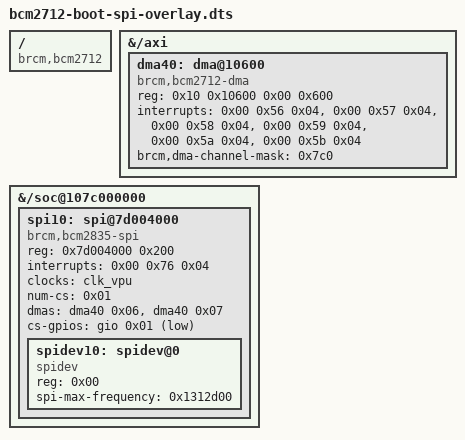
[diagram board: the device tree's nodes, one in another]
/*
 * Restore the BCM2712 boot SPI controller and the DMA engine it feeds from.
 *
 * Mainline's bcm2712.dtsi -- and so the tree in the Talos kernel image this
 * project uses as its base -- describes neither spi10 (the SPI controller in
 * front of the 2 MiB boot EEPROM) nor dma40. The downstream Raspberry Pi tree
 * describes both.
 *
 * That absence is not just a missing driver. The VPU bootloader resolves the
 * overlays it applies through the base tree's __symbols__, and the stepping
 * overlay it applies automatically on D0 silicon, bcm2712d0.dtbo, has:
 *
 *   __fixups__ {
 *       ...
 *       spi10 = "/fragment@5:target:0";
 *       dma40 = "/fragment@5/__overlay__:dmas:0", ... ;
 *   };
 *
 * One unresolved symbol drops the WHOLE overlay -- "dterror: can't find
 * symbol 'spi10'" / "Failed to resolve overlay 'bcm2712d0'" -- so without
 * these two nodes a D0 board runs with none of the D0 adaptations applied:
 * C0 pinctrl register layout, C0 alt-function numbering, C0 GIO bank widths.
 * It boots, which is what makes it hard to notice.
 *
 * Values are the downstream tree's, with the phandle references rewritten to
 * labels the base tree actually exports (clk_vpu, gio) or that this overlay
 * defines itself (dma40).
 *
 * Deliberately omitted: spi10's pinctrl-names/pinctrl-0. Those point at pin
 * group nodes inside the pinctrl block that mainline does not carry and that
 * have no label to reference. Linux therefore will not auto-mux GPIO1-4 for
 * this controller; the UEFI side does its own muxing (see
 * RPi5/Drivers/BootloaderConfigDxe/Bcm2712SpiFlash.c) and does not depend on
 * it. Add the groups here if a kernel ever needs spidev10 to work.
 */
/dts-v1/;
/plugin/;

/ {
	compatible = "brcm,bcm2712";

	fragment@0 {
		target-path = "/axi";
		__overlay__ {
			dma40: dma@10600 {
				compatible = "brcm,bcm2712-dma";
				reg = <0x10 0x10600 0x00 0x600>;
				interrupts = <0x00 0x56 0x04>,
					     <0x00 0x57 0x04>,
					     <0x00 0x58 0x04>,
					     <0x00 0x59 0x04>,
					     <0x00 0x5a 0x04>,
					     <0x00 0x5b 0x04>;
				interrupt-names = "dma6", "dma7", "dma8",
						  "dma9", "dma10", "dma11";
				#dma-cells = <0x01>;
				brcm,dma-channel-mask = <0x7c0>;
			};
		};
	};

	fragment@1 {
		target-path = "/soc@107c000000";
		__overlay__ {
			spi10: spi@7d004000 {
				compatible = "brcm,bcm2835-spi";
				reg = <0x7d004000 0x200>;
				interrupts = <0x00 0x76 0x04>;
				clocks = <&clk_vpu>;
				num-cs = <0x01>;
				#address-cells = <0x01>;
				#size-cells = <0x00>;
				status = "okay";
				/* Replaced with channels 3 and 4 by bcm2712d0.dtbo. */
				dmas = <&dma40 0x06>, <&dma40 0x07>;
				dma-names = "tx", "rx";
				/* 2712_BOOT_CS_N: soc GPIO1, active low. */
				cs-gpios = <&gio 0x01 0x01>;

				spidev10: spidev@0 {
					compatible = "spidev";
					reg = <0x00>;
					#address-cells = <0x01>;
					#size-cells = <0x00>;
					spi-max-frequency = <0x1312d00>;
					status = "okay";
				};
			};
		};
	};
};
